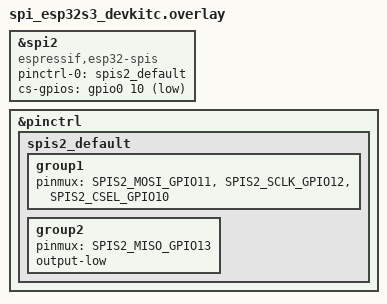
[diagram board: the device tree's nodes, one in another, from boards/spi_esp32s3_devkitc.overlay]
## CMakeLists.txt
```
#-------------------------------------------------------------------------------
# Zephyr Example Application
#
# Copyright (c) 2021 Nordic Semiconductor ASA
# SPDX-License-Identifier: Apache-2.0

cmake_minimum_required(VERSION 3.20.0)

set(ZEPHYR_EXTRA_MODULES "${CMAKE_SOURCE_DIR}/../modules/spi_test")

find_package(Zephyr REQUIRED HINTS $ENV{ZEPHYR_BASE})
project(spi_module_app)

project(app LANGUAGES C)

target_sources(app PRIVATE src/main.c)
```

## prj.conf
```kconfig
# Copyright (c) 2021 Nordic Semiconductor ASA
# SPDX-License-Identifier: Apache-2.0
#
# This file contains selected Kconfig options for the application.

CONFIG_MY_SPI_TEST=y
CONFIG_SPI=y
CONFIG_SPI_SLAVE=y
# CONFIG_IDF_TARGET_ESP32=y

CONFIG_LOG=y
CONFIG_LOG_DEFAULT_LEVEL=4
CONFIG_LOG_BACKEND_UART=y
```

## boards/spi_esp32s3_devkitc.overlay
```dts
// spi controller
&spi2 {
    // This right here expects CONFIG_ESP32_SPIM=y
	compatible = "espressif,esp32-spis";

    // already defined in zephyr/boards/espressif/esp32s3_devkitc/esp32s3_devkitc_procpu.dts
	// redundant but here for clarity
	status = "okay";
    pinctrl-0 = <&spis2_default>;
    pinctrl-names = "default";

	// custom settings; I have defined this myself.
    cs-gpios = <&gpio0 10 GPIO_ACTIVE_LOW>;
};

// already defined in zephyr/boards/espressif/esp32s3_devkitc/esp32s3_devkitc-pinctrl.dtsi
// redundant but here for clarity
&pinctrl {
	spis2_default: spis2_default {
		group1 {
			pinmux = 
                 <SPIS2_MOSI_GPIO11>,
				 <SPIS2_SCLK_GPIO12>,
				 <SPIS2_CSEL_GPIO10>;
		};

        // MOSI will be 0 on start.
        // defined in a different group because it has different settings than group 1 pins.
		group2 {
			pinmux = <SPIS2_MISO_GPIO13>;
			output-low;
		};
	};
};
```

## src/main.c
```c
#include <zephyr/drivers/spi.h>
#include <zephyr/devicetree.h>

// our own specifiers
#define LEN_TRANSCEIVE 12
#define DELAY 0
#define SPI_DEVICE_NAME spi2

// operation flags we want
static const spi_operation_t operation_flags = (

    SPI_OP_MODE_SLAVE |
    SPI_TRANSFER_MSB |
    SPI_WORD_SET(8));

static const struct device *spis_device = DEVICE_DT_GET(DT_NODELABEL(SPI_DEVICE_NAME));
static const struct spi_config spis_config = {
    .operation = operation_flags,
    .frequency = 1000000};

// static volatile const struct spi_dt_spec spi_device = SPI_DT_SPEC_GET(
//     DT_NODELABEL(SPI_DEVICE_NAME),
//     operation_flags,
//     DELAY);

int main()
{
    /*
    - I want to read four bytes so I need a four-byte array.
    - That array needs to be a member of a spi_buf
    - spi_buf needs to be a member of a spi_buf_set
    */
    // read
    uint8_t read_buf[LEN_TRANSCEIVE] = {0};
    struct spi_buf spi_read_buf = {&read_buf, LEN_TRANSCEIVE};
    const struct spi_buf_set rx_buf = {&spi_read_buf, 1};

    // write
    uint8_t write_buf[LEN_TRANSCEIVE] = {0};
    struct spi_buf spi_write_buf = {&write_buf, LEN_TRANSCEIVE};
    const struct spi_buf_set tx_buf = {&spi_write_buf, 1};

    // populate the write buffer
    for (int i = 0; i < LEN_TRANSCEIVE; i++)
        write_buf[i] = i + 4;

    // transceive
    int transceive_res = spi_transceive(spis_device, &spis_config, &tx_buf, &rx_buf);

    // transceive result should be 0 (if master, which we are) upon end.
    if (transceive_res)
    {
        printk("Error on transcceiving\n");
        return 1;
    }

    // print out what has been read
    for (int i = 0; i < LEN_TRANSCEIVE; i++)
        printk("received word %d: %d\n", i, read_buf[i]);

    return 0;
}
```
